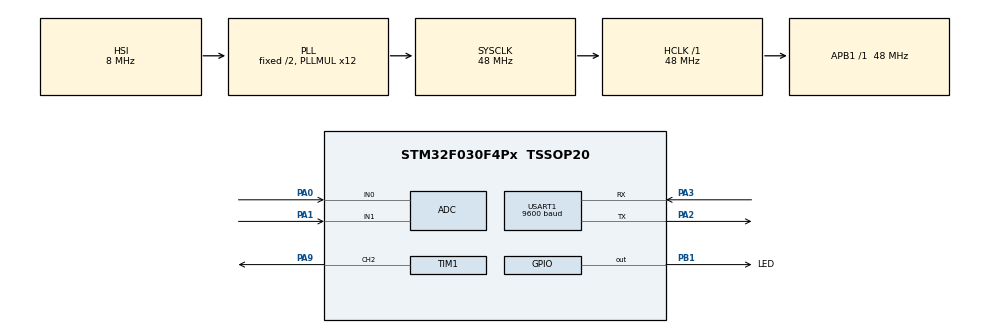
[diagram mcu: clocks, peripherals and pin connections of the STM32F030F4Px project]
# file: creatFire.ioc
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Mcu.Family=STM32F0
Mcu.Name=STM32F030F4Px
Mcu.Package=TSSOP20
NVIC.USART1_IRQn=true\:0\:0\:false\:false\:true\:true\:true\:true
PA0.Mode=IN0
PA0.Signal=ADC_IN0
PA1.Mode=IN1
PA1.Signal=ADC_IN1
PA13.Mode=Serial_Wire
PA13.Signal=SYS_SWDIO
PA14.Mode=Serial_Wire
PA14.Signal=SYS_SWCLK
PA2.Mode=Asynchronous
PA2.Signal=USART1_TX
PA3.Mode=Asynchronous
PA3.Signal=USART1_RX
PA9.GPIO_PuPd=GPIO_NOPULL
PA9.Signal=S_TIM1_CH2
PB1.GPIO_Label=LED
PB1.Signal=GPIO_Output
PF0-OSC_IN.Mode=HSE-External-Oscillator
PF0-OSC_IN.Signal=RCC_OSC_IN
PF1-OSC_OUT.Mode=HSE-External-Oscillator
PF1-OSC_OUT.Signal=RCC_OSC_OUT
ProjectManager.HeapSize=0x200
ProjectManager.StackSize=0x400
ProjectManager.TargetToolchain=STM32CubeIDE
RCC.AHBFreq_Value=48000000
RCC.APB1Freq_Value=48000000
RCC.APB1TimFreq_Value=48000000
RCC.HCLKFreq_Value=48000000
RCC.PLLMUL=RCC_PLL_MUL12
RCC.SYSCLKFreq_VALUE=48000000
RCC.SYSCLKSource=RCC_SYSCLKSOURCE_PLLCLK
SH.S_TIM1_CH2.0=TIM1_CH2,PWM Generation2 CH2
TIM1.Channel-PWM\ Generation2\ CH2=TIM_CHANNEL_2
TIM1.Period=100
TIM1.Prescaler=700
USART1.BaudRate=9600
USART1.VirtualMode-Asynchronous=VM_ASYNC
VP_TIM1_VS_ClockSourceINT.Mode=Internal
board=custom

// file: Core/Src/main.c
/* USER CODE BEGIN Header */
/**
  ******************************************************************************
  * @file           : main.c
  * @brief          : Main program body
  ******************************************************************************
  * @attention
  *
  * Copyright (c) 2024 STMicroelectronics.
  * All rights reserved.
  *
  * This software is licensed under terms that can be found in the LICENSE file
  * in the root directory of this software component.
  * If no LICENSE file comes with this software, it is provided AS-IS.
  *
  ******************************************************************************
  */
/* USER CODE END Header */
#include "main.h"
#include "adc.h"
#include "tim.h"
#include "usart.h"
#include "gpio.h"

void SystemClock_Config(void);

int main(void)
{

  /* MCU Configuration--------------------------------------------------------*/

  /* Reset of all peripherals, Initializes the Flash interface and the Systick. */
  HAL_Init();

  /* Configure the system clock */
  SystemClock_Config();

  /* Initialize all configured peripherals */
  MX_GPIO_Init();
  MX_ADC_Init();
  MX_TIM1_Init();
  MX_USART1_UART_Init();
  /* USER CODE BEGIN 2 */
  // HAL_UART_Receive_IT(&huart1, &cmd, 1);
  __HAL_TIM_SET_PRESCALER(&htim1, 700);
  __HAL_TIM_SetCompare(&htim1,TIM_CHANNEL_2,50);
  HAL_TIM_PWM_Start(&htim1, TIM_CHANNEL_2);
  /* USER CODE END 2 */

  /* Infinite loop */
  while (1)
  {

    /* USER CODE BEGIN 3 */
    // HAL_GPIO_TogglePin(LED_GPIO_Port,LED_Pin);
    // HAL_Delay(400);
  }
  /* USER CODE END 3 */
}

void SystemClock_Config(void)
{
  RCC_OscInitTypeDef RCC_OscInitStruct = {0};
  RCC_ClkInitTypeDef RCC_ClkInitStruct = {0};
  RCC_PeriphCLKInitTypeDef PeriphClkInit = {0};

  /** Initializes the RCC Oscillators according to the specified parameters
  * in the RCC_OscInitTypeDef structure.
  */
  RCC_OscInitStruct.OscillatorType = RCC_OSCILLATORTYPE_HSI|RCC_OSCILLATORTYPE_HSI14;
  RCC_OscInitStruct.HSIState = RCC_HSI_ON;
  RCC_OscInitStruct.HSI14State = RCC_HSI14_ON;
  RCC_OscInitStruct.HSICalibrationValue = RCC_HSICALIBRATION_DEFAULT;
  RCC_OscInitStruct.HSI14CalibrationValue = 16;
  RCC_OscInitStruct.PLL.PLLState = RCC_PLL_ON;
  RCC_OscInitStruct.PLL.PLLSource = RCC_PLLSOURCE_HSI;
  RCC_OscInitStruct.PLL.PLLMUL = RCC_PLL_MUL12;
  RCC_OscInitStruct.PLL.PREDIV = RCC_PREDIV_DIV1;
  if (HAL_RCC_OscConfig(&RCC_OscInitStruct) != HAL_OK)
  {
    Error_Handler();
  }

  /** Initializes the CPU, AHB and APB buses clocks
  */
  RCC_ClkInitStruct.ClockType = RCC_CLOCKTYPE_HCLK|RCC_CLOCKTYPE_SYSCLK
                              |RCC_CLOCKTYPE_PCLK1;
  RCC_ClkInitStruct.SYSCLKSource = RCC_SYSCLKSOURCE_PLLCLK;
  RCC_ClkInitStruct.AHBCLKDivider = RCC_SYSCLK_DIV1;
  RCC_ClkInitStruct.APB1CLKDivider = RCC_HCLK_DIV1;

  if (HAL_RCC_ClockConfig(&RCC_ClkInitStruct, FLASH_LATENCY_1) != HAL_OK)
  {
    Error_Handler();
  }
  PeriphClkInit.PeriphClockSelection = RCC_PERIPHCLK_USART1;
  PeriphClkInit.Usart1ClockSelection = RCC_USART1CLKSOURCE_PCLK1;
  if (HAL_RCCEx_PeriphCLKConfig(&PeriphClkInit) != HAL_OK)
  {
    Error_Handler();
  }
}

void Error_Handler(void)
{
  __disable_irq();
  while (1)
  {
  }
}
